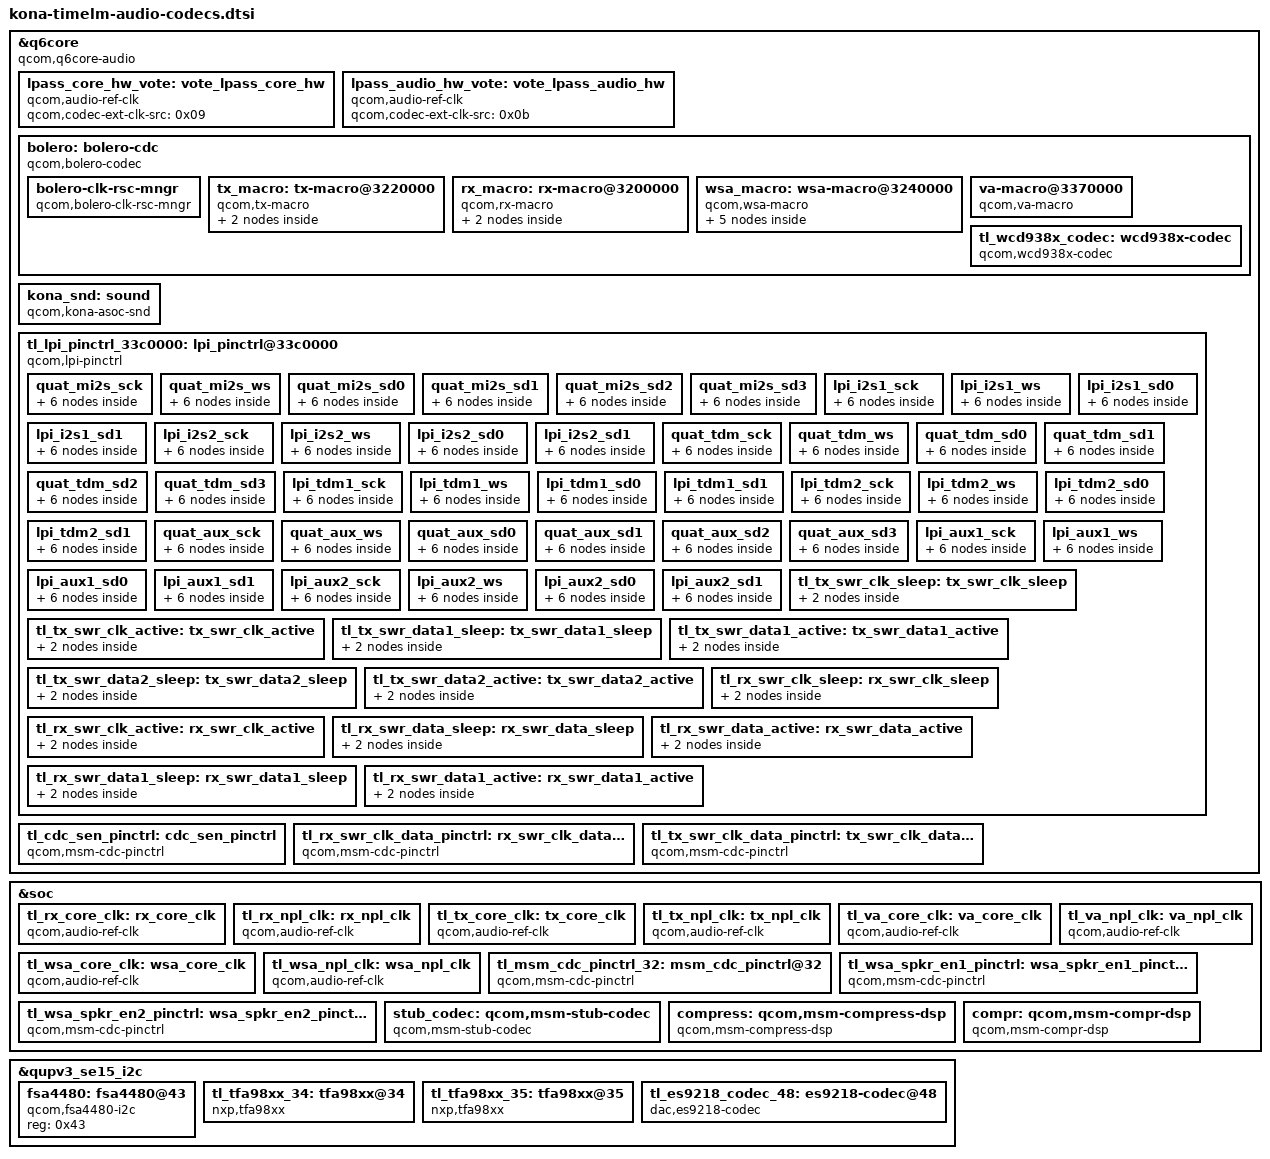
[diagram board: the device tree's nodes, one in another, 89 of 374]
/* Generated by timelm-bsp/tools/port-live-subtrees.py from v60-live.dts */

&q6core {
		compatible = "qcom,q6core-audio";

		lpass_core_hw_vote: vote_lpass_core_hw {
			compatible = "qcom,audio-ref-clk";
			qcom,codec-ext-clk-src = <0x09>;
			#clock-cells = <0x01>;
		};

		lpass_audio_hw_vote: vote_lpass_audio_hw {
			compatible = "qcom,audio-ref-clk";
			qcom,codec-ext-clk-src = <0x0b>;
			#clock-cells = <0x01>;
		};

		bolero: bolero-cdc {
			compatible = "qcom,bolero-codec";
			clock-names = "lpass_core_hw_vote", "lpass_audio_hw_vote";
			clocks = <&lpass_core_hw_vote 0x0 &lpass_audio_hw_vote 0x0>;
			qcom,num-macros = <0x04>;

			bolero-clk-rsc-mngr {
				compatible = "qcom,bolero-clk-rsc-mngr";
				qcom,fs-gen-sequence = <0x3000 0x01 0x3004 0x01 0x3080 0x02>;
				qcom,rx_mclk_mode_muxsel = <0x33240d8>;
				qcom,wsa_mclk_mode_muxsel = <0x33220d8>;
				qcom,va_mclk_mode_muxsel = <0x33a0000>;
				clock-names = "tx_core_clk", "tx_npl_clk", "rx_core_clk", "rx_npl_clk", "wsa_core_clk", "wsa_npl_clk", "va_core_clk", "va_npl_clk";
				clocks = <&tl_tx_core_clk 0x0 &tl_tx_npl_clk 0x0 &tl_rx_core_clk 0x0 &tl_rx_npl_clk 0x0 &tl_wsa_core_clk 0x0 &tl_wsa_npl_clk 0x0 &tl_va_core_clk 0x0 &tl_va_npl_clk 0x0>;
			};

			tx_macro: tx-macro@3220000 {
				compatible = "qcom,tx-macro";
				reg = <0x3220000 0x00>;
				clock-names = "tx_core_clk", "tx_npl_clk";
				clocks = <&tl_tx_core_clk 0x0 &tl_tx_npl_clk 0x0>;
				qcom,tx-swr-gpios = <&tl_tx_swr_clk_data_pinctrl>;
				qcom,tx-dmic-sample-rate = <0x249f00>;

				swr2: tx_swr_master {
					compatible = "qcom,swr-mstr";
					#address-cells = <0x02>;
					#size-cells = <0x00>;
					clock-names = "lpass_core_hw_vote", "lpass_audio_hw_vote";
					clocks = <&lpass_core_hw_vote 0x0 &lpass_audio_hw_vote 0x0>;
					qcom,swr-master-version = <0x1050001>;
					qcom,swr_master_id = <0x03>;
					qcom,mipi-sdw-block-packing-mode = <0x01>;
					swrm-io-base = <0x3230000 0x00>;
					interrupts-extended = <&intc 0x0 0x129 0x4 &pdc 0x6d 0x4>;
					interrupt-names = "swr_master_irq", "swr_wake_irq";
					qcom,swr-wakeup-required = <0x01>;
					qcom,swr-num-ports = <0x05>;
					qcom,swr-port-mapping = <0x01 0x21 0x0f 0x02 0x12 0x01 0x02 0x13 0x02 0x03 0x14 0x01 0x03 0x15 0x02 0x04 0x16 0x01 0x04 0x17 0x02 0x04 0x18 0x04 0x04 0x19 0x08 0x05 0x1a 0x01 0x05 0x1b 0x02 0x05 0x1c 0x04 0x05 0x1d 0x08>;
					qcom,swr-num-dev = <0x01>;
					qcom,swr-clock-stop-mode0 = <0x01>;
					qcom,swr-mstr-irq-wakeup-capable = <0x01>;

					tl_wcd938x_tx_slave: wcd938x-tx-slave {
						compatible = "qcom,wcd938x-slave";
						reg = <0x0d 0x1170223>;
					};
				};
			};

			rx_macro: rx-macro@3200000 {
				compatible = "qcom,rx-macro";
				reg = <0x3200000 0x00>;
				clock-names = "rx_core_clk", "rx_npl_clk";
				clocks = <&tl_rx_core_clk 0x0 &tl_rx_npl_clk 0x0>;
				qcom,rx-swr-gpios = <&tl_rx_swr_clk_data_pinctrl>;
				qcom,rx_mclk_mode_muxsel = <0x33240d8>;
				qcom,rx-bcl-pmic-params = [00 04 3e];
				qcom,default-clk-id = <0x00>;

				swr1: rx_swr_master {
					compatible = "qcom,swr-mstr";
					#address-cells = <0x02>;
					#size-cells = <0x00>;
					clock-names = "lpass_core_hw_vote", "lpass_audio_hw_vote";
					clocks = <&lpass_core_hw_vote 0x0 &lpass_audio_hw_vote 0x0>;
					qcom,swr-master-version = <0x1050001>;
					qcom,swr_master_id = <0x02>;
					qcom,mipi-sdw-block-packing-mode = <0x01>;
					swrm-io-base = <0x3210000 0x00>;
					interrupts = <0x00 0x12a 0x04>;
					interrupt-names = "swr_master_irq";
					qcom,swr-num-ports = <0x05>;
					qcom,disable-div2-clk-switch = <0x01>;
					qcom,swr-port-mapping = <0x01 0x09 0x01 0x01 0x0a 0x02 0x02 0x0d 0x01 0x03 0x0b 0x01 0x03 0x0c 0x02 0x04 0x0e 0x01 0x05 0x0f 0x01 0x05 0x10 0x02>;
					qcom,swr-num-dev = <0x01>;
					qcom,swr-clock-stop-mode0 = <0x01>;

					tl_wcd938x_rx_slave: wcd938x-rx-slave {
						compatible = "qcom,wcd938x-slave";
						reg = <0x0d 0x1170224>;
					};
				};
			};

			wsa_macro: wsa-macro@3240000 {
				compatible = "qcom,wsa-macro";
				reg = <0x3240000 0x00>;
				clock-names = "wsa_core_clk", "wsa_npl_clk";
				clocks = <&tl_wsa_core_clk 0x0 &tl_wsa_npl_clk 0x0>;
				qcom,is-used-swr-gpio = <0x00>;
				qcom,wsa-bcl-pmic-params = [00 04 3e];
				qcom,default-clk-id = <0x00>;
				qcom,wsa-swr-gpios;

				swr0: wsa_swr_master {
					status = "disabled";
					compatible = "qcom,swr-mstr";
					#address-cells = <0x02>;
					#size-cells = <0x00>;
					clock-names = "lpass_core_hw_vote", "lpass_audio_hw_vote";
					clocks = <&lpass_core_hw_vote 0x0 &lpass_audio_hw_vote 0x0>;
					qcom,swr-master-version = <0x1050001>;
					qcom,swr_master_id = <0x01>;
					qcom,mipi-sdw-block-packing-mode = <0x00>;
					swrm-io-base = <0x3250000 0x00>;
					interrupts = <0x00 0xca 0x04>;
					interrupt-names = "swr_master_irq";
					qcom,swr-num-ports = <0x08>;
					qcom,swr-port-mapping = <0x01 0x01 0x01 0x02 0x03 0x0f 0x03 0x02 0x03 0x04 0x05 0x01 0x05 0x07 0x0f 0x06 0x06 0x03 0x07 0x04 0x03 0x08 0x08 0x03>;
					qcom,swr-num-dev = <0x02>;

					wsa881x@20170211 {
						compatible = "qcom,wsa881x";
						reg = <0x10 0x20170211>;
						qcom,spkr-sd-n-node = <&tl_wsa_spkr_en1_pinctrl>;
						qcom,bolero-handle = <&bolero>;
						status = "disabled";
					};

					wsa881x@20170212 {
						compatible = "qcom,wsa881x";
						reg = <0x10 0x20170212>;
						qcom,spkr-sd-n-node = <&tl_wsa_spkr_en2_pinctrl>;
						qcom,bolero-handle = <&bolero>;
						status = "disabled";
					};

					wsa881x@21170213 {
						compatible = "qcom,wsa881x";
						reg = <0x10 0x21170213>;
						qcom,spkr-sd-n-node = <&tl_wsa_spkr_en1_pinctrl>;
						qcom,bolero-handle = <&bolero>;
						status = "disabled";
					};

					wsa881x@21170214 {
						compatible = "qcom,wsa881x";
						reg = <0x10 0x21170214>;
						qcom,spkr-sd-n-node = <&tl_wsa_spkr_en2_pinctrl>;
						qcom,bolero-handle = <&bolero>;
						status = "disabled";
					};
				};
			};

			va-macro@3370000 {
				compatible = "qcom,va-macro";
				reg = <0x3370000 0x00>;
				clock-names = "lpass_audio_hw_vote";
				clocks = <&lpass_audio_hw_vote 0x0>;
				va-vdd-micb-supply = <&pm8150_s4>;
				qcom,va-vdd-micb-voltage = <0x1b7740 0x1b7740>;
				qcom,va-vdd-micb-current = <0x2bc0>;
				qcom,va-dmic-sample-rate = <0x927c0>;
				qcom,va-clk-mux-select = <0x01>;
				qcom,va-island-mode-muxsel = <0x33a0000>;
				qcom,default-clk-id = <0x00>;
			};

			tl_wcd938x_codec: wcd938x-codec {
				compatible = "qcom,wcd938x-codec";
				qcom,split-codec = <0x01>;
				qcom,rx_swr_ch_map = <0x00 0x09 0x01 0x00 0x09 0x00 0x0a 0x02 0x00 0x0a 0x01 0x0d 0x01 0x00 0x0d 0x02 0x0b 0x01 0x00 0x0b 0x02 0x0c 0x02 0x00 0x0c 0x03 0x0e 0x01 0x00 0x0e 0x04 0x0f 0x01 0x00 0x0f 0x04 0x10 0x02 0x00 0x10>;
				qcom,tx_swr_ch_map = <0x00 0x12 0x01 0x00 0x12 0x00 0x13 0x02 0x00 0x13 0x01 0x14 0x01 0x00 0x14 0x01 0x15 0x02 0x00 0x15 0x02 0x16 0x01 0x00 0x16 0x02 0x17 0x02 0x00 0x17 0x02 0x11 0x04 0x00 0x18 0x02 0x18 0x04 0x00 0x18 0x02 0x19 0x08 0x00 0x19 0x03 0x1a 0x01 0x00 0x1a 0x03 0x1b 0x02 0x00 0x1b 0x03 0x1c 0x04 0x00 0x1c 0x03 0x1d 0x08 0x00 0x1d>;
				qcom,wcd-rst-gpio-node = <&tl_msm_cdc_pinctrl_32>;
				qcom,rx-slave = <&tl_wcd938x_rx_slave>;
				qcom,tx-slave = <&tl_wcd938x_tx_slave>;
				cdc-vdd-rxtx-supply = <&pm8150_s4>;
				qcom,cdc-vdd-rxtx-voltage = <0x1b7740 0x1b7740>;
				qcom,cdc-vdd-rxtx-current = <0x7530>;
				cdc-vddio-supply = <&pm8150_s4>;
				qcom,cdc-vddio-voltage = <0x1b7740 0x1b7740>;
				qcom,cdc-vddio-current = <0x7530>;
				cdc-vdd-buck-supply = <&pm8150_s4>;
				qcom,cdc-vdd-buck-voltage = <0x1b7740 0x1b7740>;
				qcom,cdc-vdd-buck-current = <0x9eb10>;
				cdc-vdd-mic-bias-supply = <&pm8150a_bob>;
				qcom,cdc-vdd-mic-bias-voltage = <0x324b00 0x3c6cc0>;
				qcom,cdc-vdd-mic-bias-current = <0x7530>;
				qcom,cdc-micbias1-mv = <0xa8c>;
				qcom,cdc-micbias2-mv = <0x7d0>;
				qcom,cdc-micbias3-mv = <0xa8c>;
				qcom,cdc-micbias4-mv = <0xa8c>;
				qcom,cdc-static-supplies = "cdc-vdd-rxtx", "cdc-vddio", "cdc-vdd-buck", "cdc-vdd-mic-bias";
			};
		};

		kona_snd: sound {
			compatible = "qcom,kona-asoc-snd";
			qcom,mi2s-audio-intf = <0x01>;
			qcom,auxpcm-audio-intf = <0x01>;
			qcom,tdm-audio-intf = <0x01>;
			qcom,wcn-bt = <0x0>;
			qcom,ext-disp-audio-rx = <0x0>;
			qcom,afe-rxtx-lb = <0x00>;
			clock-names = "lpass_audio_hw_vote";
			clocks = <&lpass_audio_hw_vote 0x0>;
			asoc-platform = <&pcm0 &pcm1 &pcm2 &voip &voice &loopback &compress &hostless &afe &lsm &routing &compr &pcm_noirq>;
			asoc-platform-names = "msm-pcm-dsp.0", "msm-pcm-dsp.1", "msm-pcm-dsp.2", "msm-voip-dsp", "msm-pcm-voice", "msm-pcm-loopback", "msm-compress-dsp", "msm-pcm-hostless", "msm-pcm-afe", "msm-lsm-client", "msm-pcm-routing", "msm-compr-dsp", "msm-pcm-dsp-noirq";
			asoc-cpu = <&dai_dp &dai_dp1 &dai_mi2s0 &dai_mi2s1 &dai_mi2s2 &dai_mi2s3 &dai_mi2s4 &dai_mi2s5 &dai_pri_auxpcm &dai_sec_auxpcm &dai_tert_auxpcm &dai_quat_auxpcm &dai_quin_auxpcm &dai_sen_auxpcm &afe_pcm_rx &afe_pcm_tx &afe_proxy_rx &afe_proxy_tx &incall_record_rx &incall_record_tx &incall_music_rx &incall_music_2_rx &proxy_rx &proxy_tx &usb_audio_rx &usb_audio_tx &sb_7_rx &sb_7_tx &dai_pri_tdm_rx_0 &dai_pri_tdm_tx_0 &dai_sec_tdm_rx_0 &dai_sec_tdm_tx_0 &dai_tert_tdm_rx_0 &dai_tert_tdm_tx_0 &dai_quat_tdm_rx_0 &dai_quat_tdm_tx_0 &dai_quin_tdm_rx_0 &dai_quin_tdm_tx_0 &dai_sen_tdm_rx_0 &dai_sen_tdm_tx_0 &wsa_cdc_dma_0_rx &wsa_cdc_dma_0_tx &wsa_cdc_dma_1_rx &wsa_cdc_dma_1_tx &wsa_cdc_dma_2_tx &va_cdc_dma_0_tx &va_cdc_dma_1_tx &va_cdc_dma_2_tx &rx_cdc_dma_0_rx &tx_cdc_dma_0_tx &rx_cdc_dma_1_rx &tx_cdc_dma_1_tx &rx_cdc_dma_2_rx &tx_cdc_dma_2_tx &rx_cdc_dma_3_rx &tx_cdc_dma_3_tx &rx_cdc_dma_4_rx &tx_cdc_dma_4_tx &rx_cdc_dma_5_rx &tx_cdc_dma_5_tx &rx_cdc_dma_6_rx &rx_cdc_dma_7_rx &afe_loopback_tx>;
			asoc-cpu-names = "msm-dai-q6-dp.0", "msm-dai-q6-dp.1", "msm-dai-q6-mi2s.0", "msm-dai-q6-mi2s.1", "msm-dai-q6-mi2s.2", "msm-dai-q6-mi2s.3", "msm-dai-q6-mi2s.4", "msm-dai-q6-mi2s.5", "msm-dai-q6-auxpcm.1", "msm-dai-q6-auxpcm.2", "msm-dai-q6-auxpcm.3", "msm-dai-q6-auxpcm.4", "msm-dai-q6-auxpcm.5", "msm-dai-q6-auxpcm.6", "msm-dai-q6-dev.224", "msm-dai-q6-dev.225", "msm-dai-q6-dev.241", "msm-dai-q6-dev.240", "msm-dai-q6-dev.32771", "msm-dai-q6-dev.32772", "msm-dai-q6-dev.32773", "msm-dai-q6-dev.32770", "msm-dai-q6-dev.8194", "msm-dai-q6-dev.8195", "msm-dai-q6-dev.28672", "msm-dai-q6-dev.28673", "msm-dai-q6-dev.16398", "msm-dai-q6-dev.16399", "msm-dai-q6-tdm.36864", "msm-dai-q6-tdm.36865", "msm-dai-q6-tdm.36880", "msm-dai-q6-tdm.36881", "msm-dai-q6-tdm.36896", "msm-dai-q6-tdm.36897", "msm-dai-q6-tdm.36912", "msm-dai-q6-tdm.36913", "msm-dai-q6-tdm.36928", "msm-dai-q6-tdm.36929", "msm-dai-q6-tdm.36944", "msm-dai-q6-tdm.36945", "msm-dai-cdc-dma-dev.45056", "msm-dai-cdc-dma-dev.45057", "msm-dai-cdc-dma-dev.45058", "msm-dai-cdc-dma-dev.45059", "msm-dai-cdc-dma-dev.45061", "msm-dai-cdc-dma-dev.45089", "msm-dai-cdc-dma-dev.45091", "msm-dai-cdc-dma-dev.45093", "msm-dai-cdc-dma-dev.45104", "msm-dai-cdc-dma-dev.45105", "msm-dai-cdc-dma-dev.45106", "msm-dai-cdc-dma-dev.45107", "msm-dai-cdc-dma-dev.45108", "msm-dai-cdc-dma-dev.45109", "msm-dai-cdc-dma-dev.45110", "msm-dai-cdc-dma-dev.45111", "msm-dai-cdc-dma-dev.45112", "msm-dai-cdc-dma-dev.45113", "msm-dai-cdc-dma-dev.45114", "msm-dai-cdc-dma-dev.45115", "msm-dai-cdc-dma-dev.45116", "msm-dai-cdc-dma-dev.45118", "msm-dai-q6-dev.24577";
			fsa4480-i2c-handle = <&fsa4480>;
			qcom,model = "kona-mtp-snd-card";
			qcom,msm-mi2s-master = <0x01 0x01 0x01 0x01 0x01 0x01>;
			qcom,audio-routing = "AMIC1", "MIC BIAS1", "AMIC1", "Analog Mic1", "AMIC2", "MIC BIAS2", "AMIC2", "Analog Mic2", "AMIC3", "MIC BIAS3", "AMIC3", "Analog Mic3", "AMIC4", "MIC BIAS3", "AMIC4", "Analog Mic4", "AMIC5", "MIC BIAS4", "AMIC5", "Analog Mic5", "IN1_HPHL", "HPHL_OUT", "IN2_HPHR", "HPHR_OUT", "IN3_AUX", "AUX_OUT", "TX SWR_ADC0", "ADC1_OUTPUT", "TX SWR_ADC1", "ADC2_OUTPUT", "TX SWR_ADC2", "ADC3_OUTPUT", "TX SWR_ADC3", "ADC4_OUTPUT", "WSA SRC0_INP", "SRC0", "WSA_TX DEC0_INP", "TX DEC0 MUX", "WSA_TX DEC1_INP", "TX DEC1 MUX", "RX_TX DEC0_INP", "TX DEC0 MUX", "RX_TX DEC1_INP", "TX DEC1 MUX", "RX_TX DEC2_INP", "TX DEC2 MUX", "RX_TX DEC3_INP", "TX DEC3 MUX", "VA_AIF1 CAP", "VA_SWR_CLK", "VA_AIF2 CAP", "VA_SWR_CLK", "VA_AIF3 CAP", "VA_SWR_CLK", "VA SWR_ADC0", "ADC1_OUTPUT", "VA SWR_ADC1", "ADC2_OUTPUT", "VA SWR_ADC2", "ADC3_OUTPUT", "VA SWR_ADC3", "ADC4_OUTPUT";
			qcom,msm-mbhc-hphl-swh = <0x01>;
			qcom,msm-mbhc-gnd-swh = <0x00>;
			asoc-codec = <&stub_codec &bolero &tl_tfa98xx_34 &tl_tfa98xx_35 &tl_es9218_codec_48>;
			asoc-codec-names = "msm-stub-codec.1", "bolero_codec", "tfa98xx-codec.0034", "tfa98xx-codec.0035", "es9218-codec.0048";
			qcom,wsa-max-devs = <0x00>;
			qcom,codec-max-aux-devs = <0x01>;
			qcom,codec-aux-devs = <&tl_wcd938x_codec>;
			qcom,msm_audio_ssr_devs = <&audio_apr &q6core &tl_lpi_pinctrl_33c0000 &bolero>;
			qcom,sen-mi2s-gpios = <&tl_cdc_sen_pinctrl>;
			qcom,msm-mbhc-moist-cfg = <0x00 0x00 0x02>;
		};

		tl_lpi_pinctrl_33c0000: lpi_pinctrl@33c0000 {
			compatible = "qcom,lpi-pinctrl";
			reg = <0x33c0000 0x00>;
			qcom,slew-reg = <0x355a000 0x00>;
			qcom,num-gpios = <0x0e>;
			gpio-controller;
			#gpio-cells = <0x02>;
			qcom,lpi-offset-tbl = <0x00 0x1000 0x2000 0x3000 0x4000 0x5000 0x6000 0x7000 0x8000 0x9000 0xa000 0xb000 0xc000 0xd000>;
			qcom,lpi-slew-offset-tbl = <0x00 0x02 0x04 0x08 0x0a 0x0c 0x00 0x00 0x00 0x00 0x10 0x12 0x00 0x00>;
			clock-names = "lpass_core_hw_vote", "lpass_audio_hw_vote";
			clocks = <&lpass_core_hw_vote 0x0 &lpass_audio_hw_vote 0x0>;

			quat_mi2s_sck {

				quat_mi2s_sck_sleep {

					mux {
						pins = "gpio0";
						function = "func2";
					};

					config {
						pins = "gpio0";
						drive-strength = <0x02>;
						bias-pull-down;
						input-enable;
					};
				};

				quat_mi2s_sck_active {

					mux {
						pins = "gpio0";
						function = "func2";
					};

					config {
						pins = "gpio0";
						drive-strength = <0x08>;
						bias-disable;
						output-high;
					};
				};
			};

			quat_mi2s_ws {

				quat_mi2s_ws_sleep {

					mux {
						pins = "gpio1";
						function = "func2";
					};

					config {
						pins = "gpio1";
						drive-strength = <0x02>;
						bias-pull-down;
						input-enable;
					};
				};

				quat_mi2s_ws_active {

					mux {
						pins = "gpio1";
						function = "func2";
					};

					config {
						pins = "gpio1";
						drive-strength = <0x08>;
						bias-disable;
						output-high;
					};
				};
			};

			quat_mi2s_sd0 {

				quat_mi2s_sd0_sleep {

					mux {
						pins = "gpio2";
						function = "func2";
					};

					config {
						pins = "gpio2";
						drive-strength = <0x02>;
						bias-pull-down;
						input-enable;
					};
				};

				quat_mi2s_sd0_active {

					mux {
						pins = "gpio2";
						function = "func2";
					};

					config {
						pins = "gpio2";
						drive-strength = <0x08>;
						bias-disable;
						output-high;
					};
				};
			};

			quat_mi2s_sd1 {

				quat_mi2s_sd1_sleep {

					mux {
						pins = "gpio3";
						function = "func2";
					};

					config {
						pins = "gpio3";
						drive-strength = <0x02>;
						bias-pull-down;
						input-enable;
					};
				};

				quat_mi2s_sd1_active {

					mux {
						pins = "gpio3";
						function = "func2";
					};

					config {
						pins = "gpio3";
						drive-strength = <0x08>;
						bias-disable;
						output-high;
					};
				};
			};

			quat_mi2s_sd2 {

				quat_mi2s_sd2_sleep {

					mux {
						pins = "gpio4";
						function = "func2";
					};

					config {
						pins = "gpio4";
						drive-strength = <0x02>;
						bias-pull-down;
						input-enable;
					};
				};

				quat_mi2s_sd2_active {

					mux {
						pins = "gpio4";
						function = "func2";
					};

					config {
						pins = "gpio4";
						drive-strength = <0x08>;
						bias-disable;
						output-high;
					};
				};
			};

			quat_mi2s_sd3 {

				quat_mi2s_sd3_sleep {

					mux {
						pins = "gpio5";
						function = "func4";
					};

					config {
						pins = "gpio5";
						drive-strength = <0x02>;
						bias-pull-down;
						input-enable;
					};
				};

				quat_mi2s_sd3_active {

					mux {
						pins = "gpio5";
						function = "func4";
					};

					config {
						pins = "gpio5";
						drive-strength = <0x08>;
						bias-disable;
						output-high;
					};
				};
			};

			lpi_i2s1_sck {

				lpi_i2s1_sck_sleep {

					mux {
						pins = "gpio6";
						function = "func2";
					};

					config {
						pins = "gpio6";
						drive-strength = <0x02>;
						bias-pull-down;
						input-enable;
					};
				};

				lpi_i2s1_sck_active {

					mux {
						pins = "gpio6";
						function = "func2";
					};

					config {
						pins = "gpio6";
						drive-strength = <0x08>;
						bias-disable;
						output-high;
					};
				};
			};

			lpi_i2s1_ws {

				lpi_i2s1_ws_sleep {

					mux {
						pins = "gpio7";
						function = "func2";
					};

					config {
						pins = "gpio7";
						drive-strength = <0x02>;
						bias-pull-down;
						input-enable;
					};
				};

				lpi_i2s1_ws_active {

					mux {
						pins = "gpio7";
						function = "func2";
					};

					config {
						pins = "gpio7";
						drive-strength = <0x08>;
						bias-disable;
						output-high;
					};
				};
			};

			lpi_i2s1_sd0 {

				lpi_i2s1_sd0_sleep {

					mux {
						pins = "gpio8";
						function = "func2";
					};

					config {
						pins = "gpio8";
						drive-strength = <0x02>;
						bias-pull-down;
						input-enable;
					};
				};

				lpi_i2s1_sd0_active {

					mux {
						pins = "gpio8";
						function = "func2";
					};

					config {
						pins = "gpio8";
						drive-strength = <0x08>;
						bias-disable;
						output-high;
					};
				};
			};

			lpi_i2s1_sd1 {

				lpi_i2s1_sd1_sleep {

					mux {
						pins = "gpio9";
						function = "func2";
					};

					config {
						pins = "gpio9";
						drive-strength = <0x02>;
						bias-pull-down;
						input-enable;
					};
				};

				lpi_i2s1_sd1_active {

					mux {
						pins = "gpio9";
						function = "func2";
					};

					config {
						pins = "gpio9";
						drive-strength = <0x08>;
						bias-disable;
						output-high;
					};
				};
			};

			lpi_i2s2_sck {

				tl_lpi_i2s2_sck_sleep: lpi_i2s2_sck_sleep {

					mux {
						pins = "gpio10";
						function = "func1";
					};

					config {
						pins = "gpio10";
						drive-strength = <0x02>;
						bias-pull-down;
						input-enable;
					};
				};

				tl_lpi_i2s2_sck_active: lpi_i2s2_sck_active {

					mux {
						pins = "gpio10";
						function = "func1";
					};

					config {
						pins = "gpio10";
						drive-strength = <0x08>;
						bias-disable;
						output-high;
					};
				};
			};

			lpi_i2s2_ws {

				tl_lpi_i2s2_ws_sleep: lpi_i2s2_ws_sleep {

					mux {
						pins = "gpio11";
						function = "func1";
					};

					config {
						pins = "gpio11";
						drive-strength = <0x02>;
						bias-pull-down;
						input-enable;
					};
				};

				tl_lpi_i2s2_ws_active: lpi_i2s2_ws_active {

					mux {
						pins = "gpio11";
						function = "func1";
					};

					config {
						pins = "gpio11";
						drive-strength = <0x08>;
						bias-disable;
						output-high;
					};
				};
			};

			lpi_i2s2_sd0 {

				tl_lpi_i2s2_sd0_sleep: lpi_i2s2_sd0_sleep {

					mux {
						pins = "gpio12";
						function = "func2";
					};

					config {
						pins = "gpio12";
						drive-strength = <0x02>;
						bias-pull-down;
						input-enable;
					};
				};

				tl_lpi_i2s2_sd0_active: lpi_i2s2_sd0_active {

					mux {
						pins = "gpio12";
						function = "func2";
					};

					config {
						pins = "gpio12";
						drive-strength = <0x08>;
						bias-disable;
						output-high;
					};
				};
			};

			lpi_i2s2_sd1 {

				lpi_i2s2_sd1_sleep {

					mux {
						pins = "gpio13";
						function = "func2";
					};

					config {
						pins = "gpio13";
						drive-strength = <0x02>;
						bias-pull-down;
						input-enable;
					};
				};

				lpi_i2s2_sd1_active {

					mux {
						pins = "gpio13";
						function = "func2";
					};

					config {
						pins = "gpio13";
						drive-strength = <0x08>;
						bias-disable;
						output-high;
					};
				};
			};

			quat_tdm_sck {

				quat_tdm_sck_sleep {

					mux {
						pins = "gpio0";
						function = "func2";
					};

					config {
						pins = "gpio0";
						drive-strength = <0x02>;
						bias-pull-down;
						input-enable;
					};
				};

				quat_tdm_sck_active {

					mux {
						pins = "gpio0";
						function = "func2";
					};

					config {
						pins = "gpio0";
						drive-strength = <0x08>;
						bias-disable;
						output-high;
					};
				};
			};

			quat_tdm_ws {

				quat_tdm_ws_sleep {

					mux {
						pins = "gpio1";
						function = "func2";
					};

					config {
						pins = "gpio1";
						drive-strength = <0x02>;
						bias-pull-down;
						input-enable;
					};
				};

				quat_tdm_ws_active {

					mux {
						pins = "gpio1";
						function = "func2";
					};

					config {
						pins = "gpio1";
						drive-strength = <0x08>;
						bias-disable;
						output-high;
					};
				};
			};

			quat_tdm_sd0 {

				quat_tdm_sd0_sleep {

					mux {
						pins = "gpio2";
						function = "func2";
					};

					config {
						pins = "gpio2";
						drive-strength = <0x02>;
						bias-pull-down;
						input-enable;
					};
				};

				quat_tdm_sd0_active {

					mux {
						pins = "gpio2";
						function = "func2";
					};

					config {
						pins = "gpio2";
						drive-strength = <0x08>;
						bias-disable;
						output-high;
					};
				};
			};

			quat_tdm_sd1 {

				quat_tdm_sd1_sleep {

					mux {
						pins = "gpio3";
						function = "func2";
					};

					config {
						pins = "gpio3";
						drive-strength = <0x02>;
						bias-pull-down;
						input-enable;
					};
				};

				quat_tdm_sd1_active {

					mux {
						pins = "gpio3";
						function = "func2";
					};

					config {
						pins = "gpio3";
						drive-strength = <0x08>;
						bias-disable;
						output-high;
					};
				};
			};

			quat_tdm_sd2 {

				quat_tdm_sd2_sleep {

					mux {
						pins = "gpio4";
						function = "func2";
					};

					config {
						pins = "gpio4";
						drive-strength = <0x02>;
						bias-pull-down;
						input-enable;
					};
				};

				quat_tdm_sd2_active {

					mux {
						pins = "gpio4";
						function = "func2";
					};

					config {
						pins = "gpio4";
						drive-strength = <0x08>;
						bias-disable;
						output-high;
					};
				};
			};

			quat_tdm_sd3 {

				quat_tdm_sd3_sleep {

					mux {
						pins = "gpio5";
						function = "func4";
					};

					config {
						pins = "gpio5";
						drive-strength = <0x02>;
						bias-pull-down;
						input-enable;
					};
				};

				quat_tdm_sd3_active {

					mux {
						pins = "gpio5";
						function = "func4";
					};

					config {
						pins = "gpio5";
						drive-strength = <0x08>;
						bias-disable;
						output-high;
					};
				};
			};

			lpi_tdm1_sck {

				lpi_tdm1_sck_sleep {

					mux {
						pins = "gpio6";
						function = "func2";
					};

					config {
						pins = "gpio6";
						drive-strength = <0x02>;
						bias-pull-down;
						input-enable;
					};
				};

				lpi_tdm1_sck_active {

					mux {
						pins = "gpio6";
						function = "func2";
					};

					config {
						pins = "gpio6";
						drive-strength = <0x08>;
						bias-disable;
						output-high;
					};
				};
			};

			lpi_tdm1_ws {

				lpi_tdm1_ws_sleep {

					mux {
						pins = "gpio7";
						function = "func2";
					};

					config {
						pins = "gpio7";
						drive-strength = <0x02>;
						bias-pull-down;
						input-enable;
					};
				};

				lpi_tdm1_ws_active {

					mux {
						pins = "gpio7";
						function = "func2";
					};

					config {
						pins = "gpio7";
						drive-strength = <0x08>;
						bias-disable;
						output-high;
					};
				};
			};

			lpi_tdm1_sd0 {

				lpi_tdm1_sd0_sleep {

					mux {
						pins = "gpio8";
						function = "func2";
					};

					config {
						pins = "gpio8";
						drive-strength = <0x02>;
						bias-pull-down;
						input-enable;
					};
				};

				lpi_tdm1_sd0_active {

					mux {
						pins = "gpio8";
						function = "func2";
					};

					config {
						pins = "gpio8";
						drive-strength = <0x08>;
						bias-disable;
						output-high;
					};
				};
			};

			lpi_tdm1_sd1 {

				lpi_tdm1_sd1_sleep {

					mux {
						pins = "gpio9";
						function = "func2";
					};

					config {
						pins = "gpio9";
						drive-strength = <0x02>;
						bias-pull-down;
						input-enable;
					};
				};

				lpi_tdm1_sd1_active {

					mux {
						pins = "gpio9";
						function = "func2";
					};

					config {
						pins = "gpio9";
						drive-strength = <0x08>;
						bias-disable;
						output-high;
					};
				};
			};

			lpi_tdm2_sck {

				lpi_tdm2_sck_sleep {

					mux {
						pins = "gpio10";
						function = "func1";
					};

					config {
						pins = "gpio10";
						drive-strength = <0x02>;
						bias-pull-down;
						input-enable;
					};
				};

				lpi_tdm2_sck_active {

					mux {
						pins = "gpio10";
						function = "func1";
					};

					config {
						pins = "gpio10";
						drive-strength = <0x08>;
						bias-disable;
						output-high;
					};
				};
			};

			lpi_tdm2_ws {

				lpi_tdm2_ws_sleep {

					mux {
						pins = "gpio11";
						function = "func1";
					};

					config {
						pins = "gpio11";
						drive-strength = <0x02>;
						bias-pull-down;
						input-enable;
					};
				};

				lpi_tdm2_ws_active {

					mux {
						pins = "gpio11";
						function = "func1";
					};

					config {
						pins = "gpio11";
						drive-strength = <0x08>;
						bias-disable;
						output-high;
					};
				};
			};

			lpi_tdm2_sd0 {

				lpi_tdm2_sd0_sleep {

					mux {
						pins = "gpio12";
						function = "func2";
					};

					config {
						pins = "gpio12";
						drive-strength = <0x02>;
						bias-pull-down;
						input-enable;
					};
				};

				lpi_tdm2_sd0_active {

					mux {
						pins = "gpio12";
						function = "func2";
					};

					config {
						pins = "gpio12";
						drive-strength = <0x08>;
						bias-disable;
						output-high;
					};
				};
			};

			lpi_tdm2_sd1 {

				lpi_tdm2_sd1_sleep {

					mux {
						pins = "gpio13";
						function = "func2";
					};

					config {
						pins = "gpio13";
						drive-strength = <0x02>;
						bias-pull-down;
						input-enable;
					};
				};

				lpi_tdm2_sd1_active {

					mux {
						pins = "gpio13";
						function = "func2";
					};

					config {
						pins = "gpio13";
						drive-strength = <0x08>;
						bias-disable;
						output-high;
					};
				};
			};

			quat_aux_sck {

				quat_aux_sck_sleep {

					mux {
						pins = "gpio0";
						function = "func2";
					};

					config {
						pins = "gpio0";
						drive-strength = <0x02>;
						bias-pull-down;
						input-enable;
					};
				};

				quat_aux_sck_active {

					mux {
						pins = "gpio0";
						function = "func2";
					};

					config {
						pins = "gpio0";
						drive-strength = <0x08>;
						bias-disable;
						output-high;
					};
				};
			};

			quat_aux_ws {

				quat_aux_ws_sleep {

					mux {
						pins = "gpio1";
						function = "func2";
					};

					config {
						pins = "gpio1";
						drive-strength = <0x02>;
						bias-pull-down;
						input-enable;
					};
				};

				quat_aux_ws_active {

					mux {
						pins = "gpio1";
						function = "func2";
					};

					config {
						pins = "gpio1";
						drive-strength = <0x08>;
						bias-disable;
						output-high;
					};
				};
			};

			quat_aux_sd0 {

				quat_aux_sd0_sleep {

					mux {
						pins = "gpio2";
						function = "func2";
					};

					config {
						pins = "gpio2";
						drive-strength = <0x02>;
						bias-pull-down;
						input-enable;
					};
				};

				quat_aux_sd0_active {

					mux {
						pins = "gpio2";
						function = "func2";
					};

					config {
						pins = "gpio2";
						drive-strength = <0x08>;
						bias-disable;
						output-high;
					};
				};
			};

			quat_aux_sd1 {

				quat_aux_sd1_sleep {

					mux {
						pins = "gpio3";
						function = "func2";
					};

					config {
						pins = "gpio3";
						drive-strength = <0x02>;
						bias-pull-down;
						input-enable;
					};
				};

				quat_aux_sd1_active {

					mux {
						pins = "gpio3";
						function = "func2";
					};

					config {
						pins = "gpio3";
						drive-strength = <0x08>;
						bias-disable;
						output-high;
					};
				};
			};

			quat_aux_sd2 {

				quat_aux_sd2_sleep {

					mux {
						pins = "gpio4";
						function = "func2";
					};

					config {
						pins = "gpio4";
						drive-strength = <0x02>;
						bias-pull-down;
						input-enable;
					};
				};

				quat_aux_sd2_active {

					mux {
						pins = "gpio4";
						function = "func2";
					};

					config {
						pins = "gpio4";
						drive-strength = <0x08>;
						bias-disable;
						output-high;
					};
				};
			};

			quat_aux_sd3 {

				quat_aux_sd3_sleep {

					mux {
						pins = "gpio5";
						function = "func4";
					};

					config {
						pins = "gpio5";
						drive-strength = <0x02>;
						bias-pull-down;
						input-enable;
					};
				};

				quat_aux_sd3_active {

					mux {
						pins = "gpio5";
						function = "func4";
					};

					config {
						pins = "gpio5";
						drive-strength = <0x08>;
						bias-disable;
						output-high;
					};
				};
			};

			lpi_aux1_sck {

				lpi_aux1_sck_sleep {

					mux {
						pins = "gpio6";
						function = "func2";
					};

					config {
						pins = "gpio6";
						drive-strength = <0x02>;
						bias-pull-down;
						input-enable;
					};
				};

				lpi_aux1_sck_active {

					mux {
						pins = "gpio6";
						function = "func2";
					};

					config {
						pins = "gpio6";
						drive-strength = <0x08>;
						bias-disable;
						output-high;
					};
				};
			};

			lpi_aux1_ws {

				lpi_aux1_ws_sleep {

					mux {
						pins = "gpio7";
						function = "func2";
					};

					config {
						pins = "gpio7";
						drive-strength = <0x02>;
						bias-pull-down;
						input-enable;
					};
				};

				lpi_aux1_ws_active {

					mux {
						pins = "gpio7";
						function = "func2";
					};

					config {
						pins = "gpio7";
						drive-strength = <0x08>;
						bias-disable;
						output-high;
					};
				};
			};

			lpi_aux1_sd0 {

				lpi_aux1_sd0_sleep {

					mux {
						pins = "gpio8";
						function = "func2";
					};

					config {
						pins = "gpio8";
						drive-strength = <0x02>;
						bias-pull-down;
						input-enable;
					};
				};

				lpi_aux1_sd0_active {

					mux {
						pins = "gpio8";
						function = "func2";
					};

					config {
						pins = "gpio8";
						drive-strength = <0x08>;
						bias-disable;
						output-high;
					};
				};
			};

			lpi_aux1_sd1 {

				lpi_aux1_sd1_sleep {

					mux {
						pins = "gpio9";
						function = "func2";
					};

					config {
						pins = "gpio9";
						drive-strength = <0x02>;
						bias-pull-down;
						input-enable;
					};
				};

				lpi_aux1_sd1_active {

					mux {
						pins = "gpio9";
						function = "func2";
					};

					config {
						pins = "gpio9";
						drive-strength = <0x08>;
						bias-disable;
						output-high;
					};
				};
			};

			lpi_aux2_sck {

				lpi_aux2_sck_sleep {

					mux {
						pins = "gpio10";
						function = "func1";
					};

					config {
						pins = "gpio10";
						drive-strength = <0x02>;
						bias-pull-down;
						input-enable;
					};
				};

				lpi_aux2_sck_active {

					mux {
						pins = "gpio10";
						function = "func1";
					};

					config {
						pins = "gpio10";
						drive-strength = <0x08>;
						bias-disable;
						output-high;
					};
				};
			};

			lpi_aux2_ws {

				lpi_aux2_ws_sleep {

					mux {
						pins = "gpio11";
						function = "func1";
					};

					config {
						pins = "gpio11";
						drive-strength = <0x02>;
						bias-pull-down;
						input-enable;
					};
				};

				lpi_aux2_ws_active {

					mux {
						pins = "gpio11";
						function = "func1";
					};

					config {
						pins = "gpio11";
						drive-strength = <0x08>;
						bias-disable;
						output-high;
					};
				};
			};

			lpi_aux2_sd0 {

				lpi_aux2_sd0_sleep {

					mux {
						pins = "gpio12";
						function = "func2";
					};

					config {
						pins = "gpio12";
						drive-strength = <0x02>;
						bias-pull-down;
						input-enable;
					};
				};

				lpi_aux2_sd0_active {

					mux {
						pins = "gpio12";
						function = "func2";
					};

					config {
						pins = "gpio12";
						drive-strength = <0x08>;
						bias-disable;
						output-high;
					};
				};
			};

			lpi_aux2_sd1 {

				lpi_aux2_sd1_sleep {

					mux {
						pins = "gpio13";
						function = "func2";
					};

					config {
						pins = "gpio13";
						drive-strength = <0x02>;
						bias-pull-down;
						input-enable;
					};
				};

				lpi_aux2_sd1_active {

					mux {
						pins = "gpio13";
						function = "func2";
					};

					config {
						pins = "gpio13";
						drive-strength = <0x08>;
						bias-disable;
						output-high;
					};
				};
			};

			tl_tx_swr_clk_sleep: tx_swr_clk_sleep {

				mux {
					pins = "gpio0";
					function = "func1";
					input-enable;
					bias-pull-down;
				};

				config {
					pins = "gpio0";
					drive-strength = <0x02>;
				};
			};

			tl_tx_swr_clk_active: tx_swr_clk_active {

				mux {
					pins = "gpio0";
					function = "func1";
				};

				config {
					pins = "gpio0";
					drive-strength = <0x02>;
					slew-rate = <0x01>;
					bias-disable;
				};
			};

			tl_tx_swr_data1_sleep: tx_swr_data1_sleep {

				mux {
					pins = "gpio1";
					function = "func1";
				};

				config {
					pins = "gpio1";
					drive-strength = <0x02>;
					input-enable;
					bias-bus-hold;
				};
			};

			tl_tx_swr_data1_active: tx_swr_data1_active {

				mux {
					pins = "gpio1";
					function = "func1";
				};

				config {
					pins = "gpio1";
					drive-strength = <0x02>;
					slew-rate = <0x01>;
					bias-bus-hold;
				};
			};

			tl_tx_swr_data2_sleep: tx_swr_data2_sleep {

				mux {
					pins = "gpio2";
					function = "func1";
				};

				config {
					pins = "gpio2";
					drive-strength = <0x02>;
					input-enable;
					bias-pull-down;
				};
			};

			tl_tx_swr_data2_active: tx_swr_data2_active {

				mux {
					pins = "gpio2";
					function = "func1";
				};

				config {
					pins = "gpio2";
					drive-strength = <0x02>;
					slew-rate = <0x01>;
					bias-bus-hold;
				};
			};

			tl_rx_swr_clk_sleep: rx_swr_clk_sleep {

				mux {
					pins = "gpio3";
					function = "func1";
				};

				config {
					pins = "gpio3";
					drive-strength = <0x02>;
					input-enable;
					bias-pull-down;
				};
			};

			tl_rx_swr_clk_active: rx_swr_clk_active {

				mux {
					pins = "gpio3";
					function = "func1";
				};

				config {
					pins = "gpio3";
					drive-strength = <0x02>;
					slew-rate = <0x01>;
					bias-disable;
				};
			};

			tl_rx_swr_data_sleep: rx_swr_data_sleep {

				mux {
					pins = "gpio4";
					function = "func1";
				};

				config {
					pins = "gpio4";
					drive-strength = <0x02>;
					input-enable;
					bias-pull-down;
				};
			};

			tl_rx_swr_data_active: rx_swr_data_active {

				mux {
					pins = "gpio4";
					function = "func1";
				};

				config {
					pins = "gpio4";
					drive-strength = <0x02>;
					slew-rate = <0x01>;
					bias-bus-hold;
				};
			};

			tl_rx_swr_data1_sleep: rx_swr_data1_sleep {

				mux {
					pins = "gpio5";
					function = "func2";
				};

				config {
					pins = "gpio5";
					drive-strength = <0x02>;
					input-enable;
					bias-pull-down;
				};
			};

			tl_rx_swr_data1_active: rx_swr_data1_active {

				mux {
					pins = "gpio5";
					function = "func2";
				};

				config {
					pins = "gpio5";
					drive-strength = <0x02>;
					slew-rate = <0x01>;
					bias-bus-hold;
				};
			};
		};

		tl_cdc_sen_pinctrl: cdc_sen_pinctrl {
			compatible = "qcom,msm-cdc-pinctrl";
			pinctrl-names = "aud_active", "aud_sleep";
			pinctrl-0 = <&tl_lpi_i2s2_sck_active &tl_lpi_i2s2_ws_active &tl_lpi_i2s2_sd0_active>;
			pinctrl-1 = <&tl_lpi_i2s2_sck_sleep &tl_lpi_i2s2_ws_sleep &tl_lpi_i2s2_sd0_sleep>;
			qcom,lpi-gpios;
		};

		tl_rx_swr_clk_data_pinctrl: rx_swr_clk_data_pinctrl {
			compatible = "qcom,msm-cdc-pinctrl";
			pinctrl-names = "aud_active", "aud_sleep";
			pinctrl-0 = <&tl_rx_swr_clk_active &tl_rx_swr_data_active &tl_rx_swr_data1_active>;
			pinctrl-1 = <&tl_rx_swr_clk_sleep &tl_rx_swr_data_sleep &tl_rx_swr_data1_sleep>;
			qcom,lpi-gpios;
		};

		tl_tx_swr_clk_data_pinctrl: tx_swr_clk_data_pinctrl {
			compatible = "qcom,msm-cdc-pinctrl";
			pinctrl-names = "aud_active", "aud_sleep";
			pinctrl-0 = <&tl_tx_swr_clk_active &tl_tx_swr_data1_active &tl_tx_swr_data2_active>;
			pinctrl-1 = <&tl_tx_swr_clk_sleep &tl_tx_swr_data1_sleep &tl_tx_swr_data2_sleep>;
			qcom,lpi-gpios;
			qcom,tlmm-gpio = <0x93>;
		};
};

&soc {
		tl_rx_core_clk: rx_core_clk {
			compatible = "qcom,audio-ref-clk";
			qcom,codec-ext-clk-src = <0x05>;
			qcom,codec-lpass-ext-clk-freq = <0x1588800>;
			qcom,codec-lpass-clk-id = <0x30e>;
			#clock-cells = <0x01>;
		};
};

&soc {
		tl_rx_npl_clk: rx_npl_clk {
			compatible = "qcom,audio-ref-clk";
			qcom,codec-ext-clk-src = <0x06>;
			qcom,codec-lpass-ext-clk-freq = <0x1588800>;
			qcom,codec-lpass-clk-id = <0x30f>;
			#clock-cells = <0x01>;
		};
};

&soc {
		tl_tx_core_clk: tx_core_clk {
			compatible = "qcom,audio-ref-clk";
			qcom,codec-ext-clk-src = <0x07>;
			qcom,codec-lpass-ext-clk-freq = <0x124f800>;
			qcom,codec-lpass-clk-id = <0x30c>;
			#clock-cells = <0x01>;
		};
};

&soc {
		tl_tx_npl_clk: tx_npl_clk {
			compatible = "qcom,audio-ref-clk";
			qcom,codec-ext-clk-src = <0x08>;
			qcom,codec-lpass-ext-clk-freq = <0x124f800>;
			qcom,codec-lpass-clk-id = <0x30d>;
			#clock-cells = <0x01>;
		};
};

&soc {
		tl_va_core_clk: va_core_clk {
			compatible = "qcom,audio-ref-clk";
			qcom,codec-ext-clk-src = <0x02>;
			qcom,codec-lpass-ext-clk-freq = <0x124f800>;
			qcom,codec-lpass-clk-id = <0x30b>;
			#clock-cells = <0x01>;
		};
};

&soc {
		tl_va_npl_clk: va_npl_clk {
			compatible = "qcom,audio-ref-clk";
			qcom,codec-ext-clk-src = <0x0a>;
			qcom,codec-lpass-ext-clk-freq = <0x124f800>;
			qcom,codec-lpass-clk-id = <0x310>;
			#clock-cells = <0x01>;
		};
};

&soc {
		tl_wsa_core_clk: wsa_core_clk {
			compatible = "qcom,audio-ref-clk";
			qcom,codec-ext-clk-src = <0x03>;
			qcom,codec-lpass-ext-clk-freq = <0x124f800>;
			qcom,codec-lpass-clk-id = <0x309>;
			#clock-cells = <0x01>;
		};
};

&soc {
		tl_wsa_npl_clk: wsa_npl_clk {
			compatible = "qcom,audio-ref-clk";
			qcom,codec-ext-clk-src = <0x04>;
			qcom,codec-lpass-ext-clk-freq = <0x124f800>;
			qcom,codec-lpass-clk-id = <0x30a>;
			#clock-cells = <0x01>;
		};
};

&soc {
		tl_msm_cdc_pinctrl_32: msm_cdc_pinctrl@32 {
			compatible = "qcom,msm-cdc-pinctrl";
			pinctrl-names = "aud_active", "aud_sleep";
			pinctrl-0 = <&wcd938x_reset_active>;
			pinctrl-1 = <&wcd938x_reset_sleep>;
		};
};

&soc {
		tl_wsa_spkr_en1_pinctrl: wsa_spkr_en1_pinctrl {
			compatible = "qcom,msm-cdc-pinctrl";
			pinctrl-names = "aud_active", "aud_sleep";
			pinctrl-0 = <&spkr_1_sd_n_active>;
			pinctrl-1 = <&spkr_1_sd_n_sleep>;
		};
};

&soc {
		tl_wsa_spkr_en2_pinctrl: wsa_spkr_en2_pinctrl {
			compatible = "qcom,msm-cdc-pinctrl";
			pinctrl-names = "aud_active", "aud_sleep";
			pinctrl-0 = <&spkr_2_sd_n_active>;
			pinctrl-1 = <&spkr_2_sd_n_sleep>;
		};
};

&soc {
		stub_codec: qcom,msm-stub-codec {
			compatible = "qcom,msm-stub-codec";
		};
};

&soc {
		compress: qcom,msm-compress-dsp {
			compatible = "qcom,msm-compress-dsp";
		};
};

&soc {
		compr: qcom,msm-compr-dsp {
			compatible = "qcom,msm-compr-dsp";
		};
};

&qupv3_se15_i2c {
		fsa4480: fsa4480@43 {
			compatible = "qcom,fsa4480-i2c";
			reg = <0x43>;
		};
};

&qupv3_se15_i2c {
		tl_tfa98xx_34: tfa98xx@34 {
			compatible = "nxp,tfa98xx";
			status = "ok";
			reg = <0x34>;
			reset-gpio = <&tlmm 0x63 0x0>;
			reset-polarity = <0x00>;
			nxp,firmware-name = "Tfa98xx.cnt";
		};
};

&qupv3_se15_i2c {
		tl_tfa98xx_35: tfa98xx@35 {
			compatible = "nxp,tfa98xx";
			status = "ok";
			reg = <0x35>;
			nxp,firmware-name = "Tfa98xx.cnt";
		};
};

&qupv3_se15_i2c {
		tl_es9218_codec_48: es9218-codec@48 {
			compatible = "dac,es9218-codec";
			status = "ok";
			reg = <0x48>;
			dac,use-internal-ldo;
			dac,power-gpio = <&pm8150_gpios 0xa 0x0>;
			dac,hph-sw = <&pm8150_gpios 0x9 0x0>;
			dac,reset-gpio = <&tlmm 0x16 0x0>;
			/*
			 * dac,switch-gpio, dac,es9219 and the hifi_mclk clock
			 * differ per board revision: kona-timelm_common-sound_rev-b.dtsi
			 * and kona-timelm_common-sound_rev-b1.dtsi (LG
			 * kona-timelm_*-sound_rev-b{,1}.dtsi).
			 */
		};
};

